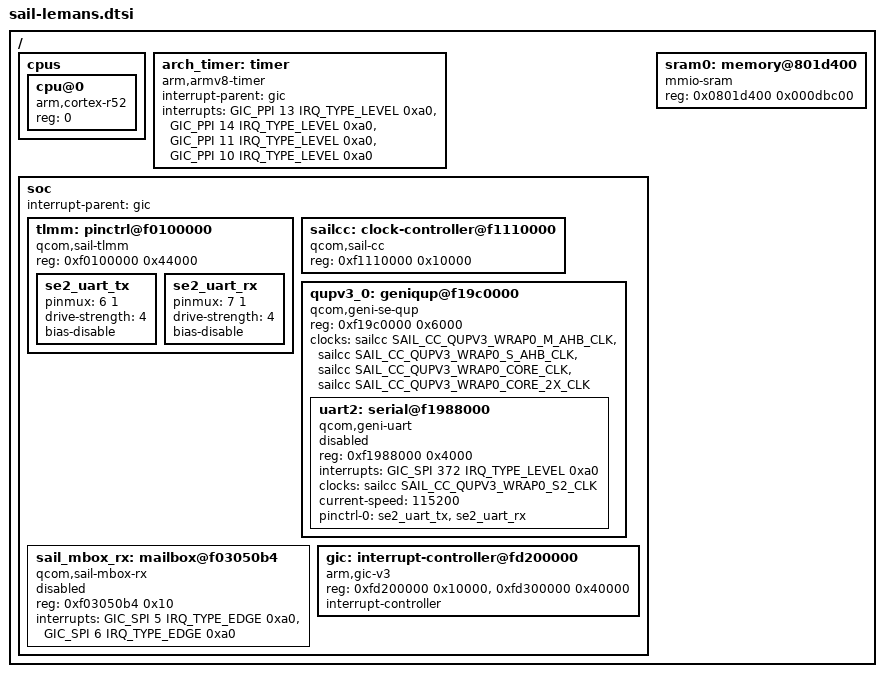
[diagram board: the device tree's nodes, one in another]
/*
 * Copyright The Zephyr Project Contributors
 * SPDX-License-Identifier: Apache-2.0
 */

#include <arm/armv8-r.dtsi>
#include <zephyr/dt-bindings/interrupt-controller/arm-gic.h>
#include <zephyr/dt-bindings/clock/qcom-sail-cc.h>

/ {
	cpus {
		#address-cells = <1>;
		#size-cells = <0>;

		cpu@0 {
			compatible = "arm,cortex-r52";
			reg = <0>;
			device_type = "cpu";
		};
	};

	arch_timer: timer {
		compatible = "arm,armv8-timer";
		interrupt-parent = <&gic>;
		interrupts = <GIC_PPI 13 IRQ_TYPE_LEVEL 0xa0>,
			     <GIC_PPI 14 IRQ_TYPE_LEVEL 0xa0>,
			     <GIC_PPI 11 IRQ_TYPE_LEVEL 0xa0>,
			     <GIC_PPI 10 IRQ_TYPE_LEVEL 0xa0>;
	};

	soc {
		interrupt-parent = <&gic>;

		tlmm: pinctrl@f0100000 {
			compatible = "qcom,sail-tlmm";
			reg = <0xf0100000 0x44000>;

			se2_uart_tx: se2_uart_tx {
				pinmux = <6 1>;
				drive-strength = <4>;
				bias-disable;
			};

			se2_uart_rx: se2_uart_rx {
				pinmux = <7 1>;
				drive-strength = <4>;
				bias-disable;
			};
		};

		sailcc: clock-controller@f1110000 {
			compatible = "qcom,sail-cc";
			reg = <0xf1110000 0x10000>;
			#clock-cells = <1>;
		};

		qupv3_0: geniqup@f19c0000 {
			compatible = "qcom,geni-se-qup";
			reg = <0xf19c0000 0x6000>;
			clocks = <&sailcc SAIL_CC_QUPV3_WRAP0_M_AHB_CLK>,
				 <&sailcc SAIL_CC_QUPV3_WRAP0_S_AHB_CLK>,
				 <&sailcc SAIL_CC_QUPV3_WRAP0_CORE_CLK>,
				 <&sailcc SAIL_CC_QUPV3_WRAP0_CORE_2X_CLK>;
			#address-cells = <1>;
			#size-cells = <1>;
			ranges;

			uart2: serial@f1988000 {
				compatible = "qcom,geni-uart";
				reg = <0xf1988000 0x4000>;
				interrupts = <GIC_SPI 372 IRQ_TYPE_LEVEL 0xa0>;
				clocks = <&sailcc SAIL_CC_QUPV3_WRAP0_S2_CLK>;
				current-speed = <115200>;
				pinctrl-0 = <&se2_uart_tx &se2_uart_rx>;
				pinctrl-names = "default";
				status = "disabled";
			};
		};

		sail_mbox_rx: mailbox@f03050b4 {
			compatible = "qcom,sail-mbox-rx";
			reg = <0xf03050b4 0x10>;
			interrupts = <GIC_SPI 5 IRQ_TYPE_EDGE 0xa0>,
				     <GIC_SPI 6 IRQ_TYPE_EDGE 0xa0>;
			interrupt-names = "nonsecure", "secure";
			#mbox-cells = <1>;
			status = "disabled";
		};

		gic: interrupt-controller@fd200000 {
			compatible = "arm,gic-v3", "arm,gic";
			reg = <0xfd200000 0x10000>,
			      <0xfd300000 0x40000>;
			interrupt-controller;
			#interrupt-cells = <4>;
			status = "okay";
		};
	};

	sram0: memory@801d400 {
		compatible = "mmio-sram";
		reg = <0x0801d400 0x000dbc00>;
	};
};
